# AES128 register map
Vendor: Texas Instruments
Peripheral module from a debugger description file (folder UCD3138R064RSM).
Registers are 32-bit, write-only, no defined reset value unless marked. A register's access mark holds for its fields unless they carry their own. Offsets are as the file gives them; lines under a group give offsets from that group; [hi:lo] are bit positions; {n}, {i} and the like mark numbered series; 'fields as' and 'values as' point back to an identical list; <NAME> marks a mode.

## AES128 — The AES-128 crypto peripheral accellerates AES-128 block cipher encryption and decryption. The peripheral does also offer hardware features to accellerate cipher modes implemented in software: * CBC-MAC * CBC * CTR * CFB * OFB * PCBC The module provides two data registers that can be input to AES operation. These are termed TXT and BUF. TXT is the AES-128 work buffer, and content changes during an AES operation. Software cannot update TXT during an ongoing AES operation. BUF is an auxiliary 128-bit buffer with multiple purposes: * initialization vector(IV) storage * counter in CTR cipher mode * hold next value of TXT Software can update BUF during an AES operation. This allows software to write next TXT during an ongoing AES operation and hence save AES idle times. INTERNAL_NOTE: The crypto module registers KEY, roundkey, BUF, and TXT and are repurposed as PBIST instruction memory when dft_pbist_testctrl input is active. Switching between the functional and PBIST modes of operation assumes all registers become corrupted, and application must initialize registers before use.
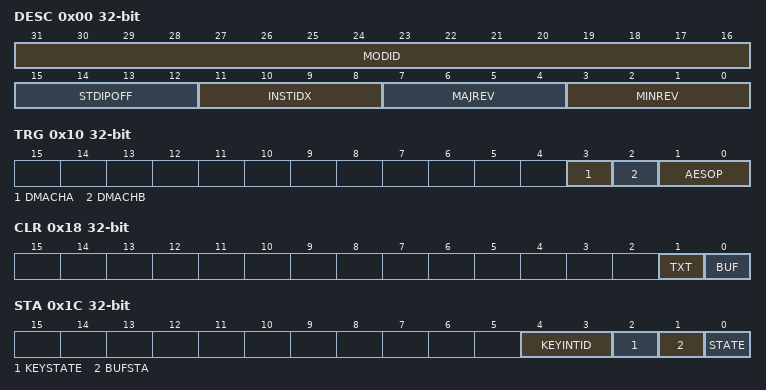
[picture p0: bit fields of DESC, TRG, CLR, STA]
0x00 DESC ro — Description Register. This register provides IP module ID, revision information, instance index and standard MMR registers offset.
  [31:16] MODID — Module Identifier This register is used to uniquely identify this IP.
  [15:12] STDIPOFF — Standard IP MMR block offset Standard IP MMRs are the set from aggregated IRQ registers till DTB. 0: Standard IP MMRs do not exist. 0x1-0xF: Standard IP MMRs begin at offset of 64*[STDIPOFF] from the base IP address.
  [11:8] INSTIDX — IP Instance ID number If multiple instances of IP exist in the device, this field can identify the instance number (0-15).
  [7:4] MAJREV — Major revision of IP (0-15)
  [3:0] MINREV — Minor Revision of IP(0-15)
0x10 TRG — Trigger This register is used to manually trigger operations.
  [3] DMACHA — Manually trigger channel A request
    0=NOEFF (Writing 0 has no effect); 1=SET (Triggers channel A request)
  [2] DMACHB — Manually trigger channel B request
    0=NOEFF (Writing 0 has no effect); 1=SET (Triggers channel B request)
  [1:0] AESOP — AES Operation Write an enumerated value to this field when [STA.STATE] = IDLE to manually trigger an AES operation. If condition is not met, the trigger is ignored. Non-enumerated values are ignored. Enumerated value indicates source of AES operation
    1=TXT (TXT = AES(KEY,TXT)); 2=BUF (TXT = AES(KEY,BUF)); 3=TXTXBUF (TXT = AES(KEY, TXT XOR BUF))
0x14 ABORT — Abort This register is used to abort current AES operation.
  [0] ABORTAES — Abort AES operation Abort an ongoing AES operation. An abort will clear TXT, BUF, DMA, AUTOCFG registers
    0=NOEFF (Writing 0 has no effect); 1=SET (Aborts an ongoing AES operation)
0x18 CLR — Clear This register is used to clear contents of TXT and BUF when [STA.STATE] = IDLE. If condition is not met, the contents remain unchanged.
  [1] TXT — Clear TXT
    0=NOEFF (Writing 0 has no effect); 1=CLR (Clears TXT)
  [0] BUF — Clear BUF
    0=NOEFF (Writing 0 has no effect); 1=CLR (Clears BUF)
0x1C STA ro — Status This register provides information on AES accellerator state and BUF status.
  [4:3] KEYINTID — KEY Initiator ID ID of the most recent AHB Initiator which has written into one of the [KEY0] to [KEY3] registers
    0=CORE (KEY was last written by CM33); 3=HSM (KEY was last written by HSM)
  [2] KEYSTATE — KEY State Indicates whether data in [KEY0] to [KEY3] is valid or not. AES operations are not allowed until KEY is valid
    0=INVALID ([KEY0] to [KEY3] are partially written or empty. Hence they do not have valid KEY value. AES operations are not allowed); 1=VALID ([KEY0] to [KEY3] are completely written by same AHB Initiator . Hence they have valid KEY value. AES operations are allowed.)
  [1] BUFSTA — BUF Status Field gives the status of BUF, indicating EMPTY or FULL, when [AUTOCFG.TRGAES] = WRBUF3. If [AUTOCFG.TRGAES] != WRBUF3, then [STA.BUFSTA] will hold the value 0. Note : Useful for CBC-MAC
    0=EMPTY (Data stored in BUF is already consumed by the AES engine and next block of data can be written in BUF.); 1=FULL (Data stored in BUF is not yet consumed by the AES engine. Next block of data cannot be written into BUF until [STA.STATE] = IDLE.)
  [0] STATE — State Field gives the state of the AES engine.
    0=IDLE (AES engine is IDLE); 1=BUSY (AES operation active)
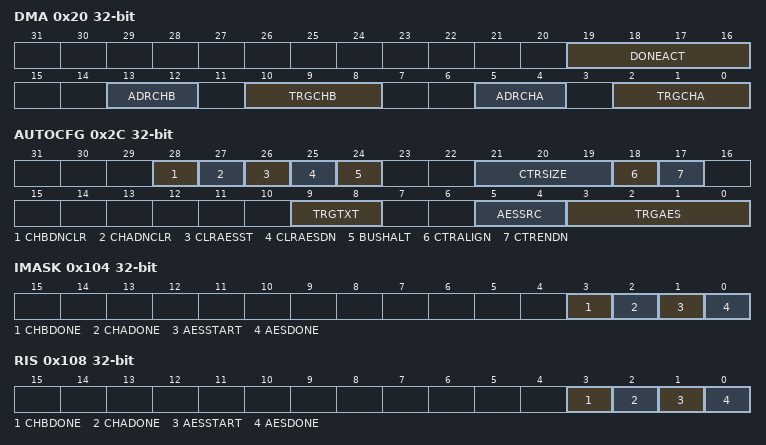
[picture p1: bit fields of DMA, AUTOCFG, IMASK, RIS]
0x20 DMA rw — Direct Memory Access This register controls the conditions that will generate burst requests on each DMA channel.
  [19:16] DONEACT — Done Action This field determines the side effects of DMA done. It is allowed to configure this field with an OR-combination of supported enums, with the exception that GATE_TRGAES_ON_CHA and GATE_TRGAES_ON_CHA_DEL must be mutually exclusive
    0=DIS (DMA done has no side effect); 1=GATE_TRGAES_ON_CHA (Triggers defined in [AUTOCFG.TRGAES] are gated when [RIS.CHADONE] = SET); 2=GATE_TRGAES_ON_CHA_DEL (Delayed gating of triggers defined in [AUTOCFG.TRGAES] Due to the pipelining of BUF writes, in certain modes, DMA CHA Done appears before the last but one AES operation has completed. Setting this bit, will gate the triggers defined in [AUTOCFG.TRGAES] only after the last write by CHA is consumed by AES FSM. Used in ECB,CBC,CBC-MAC modes (having multiple blocks encryption/decryption) to avoid spurious AES operation triggered on last read by CHB. For single mode operation, [DMA.GATE_TRGAES_ON_CHA] must be used.); 4=CLR_TXT_ON_CHA (DMA channel A done event clears [TXT0.*] thru [TXT3.*] if [STA.STATE] = IDLE. Event is ignored if condition is not met.); 8=CLR_TXT_ON_CHB (DMA channel B done event clears [TXT0.*] thru [TXT3.*] if [STA.STATE] = IDLE. Event is ignored if condition is not met.)
  [13:12] ADRCHB — Channel B Read Write Address The DMA accesses [DMACHB.*] to read or write contents of TXT and BUF as a response to a burst request. This field specifes the start address of the first DMA transfer that follows the burst request. The internal address gets incremented automatically for subsequent accesses. The DMA can transfer 8-bit, 16-bit, or 32-bit words, and must always complete a 16-byte transfer before re-arbitration. INTERNAL_NOTE: Upon each channel B request, the internal address counter gets re-initialized to 0.
    0=TXT0 (Start address is [TXT0.*]); 1=TXTX0 (Start address is [TXTX0.*]); 2=BUF0 (Start address is [BUF0.*]); 3=TXTXBUF0 (Start address is [TXTXBUF0.*])
  [10:8] TRGCHB — Channel B Trigger Select the condition that triggers DMA channel B request. Non-enumerated values are not supported and ignored.
    0=DIS (DMA requests are disabled); 1=AESSTART (Start of AES operation triggers request); 2=AESDONE (Completion of AES operation triggers request); 3=WRTXT3 (Writes to [TXT3.*], [TXTX3.*], or [TXTXBUF3.*] trigger request INTERNAL_NOTE: Useful for CFB encryption.); 4=RDTXT3 (Reads of [TXT3.*], or [TXTXBUF3.*] trigger request INTERNAL_NOTE: Useful for PCBC encryption.)
  [5:4] ADRCHA — Channel A Read Write Address The DMA accesses [DMACHA.*] to read or write contents of TXT and BUF as a response to a burst request. This field specifes the start address of the first DMA transfer that follows the burst request. The internal address gets incremented automatically for subsequent accesses. The DMA can transfer 8-bit, 16-bit, or 32-bit words, and must always complete a 16-byte transfer before re-arbitration. INTERNAL_NOTE: Upon each channel A request, the internal address counter gets re-initialized to 0.
    values as ADRCHB
  [2:0] TRGCHA — Channel A Trigger Select the condition that triggers DMA channel A request. Non-enumerated values are not supported and ignored.
    0=DIS (DMA requests are disabled); 1=AESSTART (Start of AES operation triggers request); 2=AESDONE (Completion of AES operation triggers request); 3=WRTXT3 (Writes to [TXT3.*] or [TXTX3.*] trigger request INTERNAL_NOTE: Useful for CFB encryption.); 4=RDTXT3 (Reads of [TXT3.*] or [TXTXBUF3.*] trigger request INTERNAL_NOTE: Useful for PCBC encryption.)
0x24 DMACHA rw — DMA Channel A data transfer DMA accesses this register to read or write contents from sequential addresses specifed by [DMA.ADRCHA].
  [31:0] VAL — Value transferred through DMA Channel A
0x28 DMACHB rw — DMA Channel B data transfer DMA accesses this register to read or write contents from sequential addresses specifed by [DMA.ADRCHB].
  [31:0] VAL — Value transferred through DMA Channel B
0x2C AUTOCFG rw — Automatic Configuration This register configures automatic hardware updates to TXT and BUF. Configure this register to reduce software overhead during cipher modes.
  [28] CHBDNCLR — This field enable auto-clear of [RIS.CHBDONE] interrupt on read/write of [TXT3.*]/[BUF3.*]/[TXTX3.*]/[TXTXBUF3.*] . INTERNAL_NOTE: If conditions for setting and clearing of interrupts occur at the same time, interrupt set will take priority over clear.
    0=DIS (Disable auto-clear of [RIS.CHBDONE] interrupt); 1=EN (Enable auto-clear of [RIS.CHBDONE] interrupt)
  [27] CHADNCLR — This field enables auto-clear of [RIS.CHADONE] interrupt on read/write of [TXT3.*]/[BUF3.*]/[TXTX3.*]/[TXTXBUF3.*] . INTERNAL_NOTE: If conditions for setting and clearing of interrupts occur at the same time, interrupt set will take priority over clear.
    0=DIS (Disable auto-clear of [RIS.CHADONE] interrupt); 1=EN (Enable auto-clear of [RIS.CHADONE] interrupt)
  [26] CLRAESST — Clear AES Start This field enables auto-clear of [RIS.AESSTART] interrupt on read/write of [TXT3.*]/[BUF3.*]/[TXTX3.*]/[TXTXBUF3.*] . INTERNAL_NOTE: If conditions for setting and clearing of interrupts occur at the same time, interrupt set will take priority over clear.
    0=DIS (Disable auto-clear of [RIS.AESSTART] interrupt); 1=EN (Enable auto-clear of [RIS.AESSTART] interrupt)
  [25] CLRAESDN — Clear AES Done This field enables auto-clear of [RIS.AESDONE] interrupt on read/write of [TXT3.*]/[BUF3.*]/[TXTX3.*]/[TXTXBUF3.*] . INTERNAL_NOTE: If conditions for setting and clearing of interrupts occur at the same time, interrupt set will take priority over clear.
    0=DIS (Disable auto-clear of [RIS.AESDONE] interrupt); 1=EN (Enable auto-clear of [RIS.AESDONE] interrupt)
  [24] BUSHALT — Bus Halt This field decides if bus halts on access to KEY, TXT, BUF, TXTX and TXTXBUF when [STA.STATE] = BUSY.
    0=DIS (Disable bus halt When [STA.STATE] = BUSY, writes to KEY, TXT, TXTX are ignored, reads from TXT, TXTXBUF return zero. When [STA.STATE] = BUSY and if either [STA.BUFSTA] = FULL or [AUTOCFG.CTRSIZE] != DISABLE, writes to BUF are ignored, reads return zero.); 1=EN (Enable bus halt When [STA.STATE] = BUSY, access to KEY, TXT, TXTX, TXTXBUF halt the bus until [STA.STATE] = IDLE. When [STA.STATE] = BUSY and if either [STA.BUFSTA] = FULL or [AUTOCFG.CTRSIZE] != DISABLE, access to BUF halts the bus until [STA.STATE] = IDLE.)
  [21:19] CTRSIZE — Counter Size Configures size of counter as either 8,16,32,64 or 128 Non-enumerated values are not supported and ignored
    0=DIS (Disable CTR operation); 1=CTR8 (Configures counter size as 8-bit); 2=CTR16 (Configures counter size as 16-bit); 3=CTR32 (Configures counter size as 32-bit); 4=CTR64 (Configures counter size as 64-bit); 5=CTR128 (Configures counter size as 128-bit)
  [18] CTRALIGN — Counter Alignment Specifies alignment of counter
    0=LEFTALIGN (Indicates Left Aligned Counter Not applicable for 128-bit counter size. For 128-bit counter, all octets will be considered When left aligned,,octet 0-7 will be considered , based on counter size and endianness); 1=RIGHTALIGN (Indicates right aligned counter Not applicable when counter size is 128-bit For 128-bit counter, all octets will be considered If right aligned, octet 8-15 will be considered based on endianness and counter size)
  [17] CTRENDN — Counter Endianness Specifies Endianness of counter
    0=LITTLEENDIAN (Specifies Little Endian Counter Carry will flow from octet 'n' to octet 'n+1'); 1=BIGENDIAN (Specifies Big Endian Counter Carry will flow from octet 'n' to octet 'n-1')
  [9:8] TRGTXT — Trigger for TXT This field determines if and when hardware automatically XORs BUF into TXT. Non-enumerated values are not supported and ignored. It is allowed to configure this field with an OR-combination of supported enums.
    0=DIS (No hardware update of TXT); 1=RDTXT3 (Hardware XORs content of BUF into TXT upon read of [TXT3.*]); 2=RDTXTXBUF3 (Hardware XORs content of BUF into TXT upon read of [TXTXBUF3.*])
  [5:4] AESSRC — AES Source This field specifies the data source to hardware-triggered AES operations. Non-enumerated values are not supported and ignored. INTERNAL_NOTE: Forward AES-128 with field set to BUF or TXTXBUF will need an additional clock cycle to complete. There is room for one more data input if later identified.
    values as TRG.AESOP
  [3:0] TRGAES — Trigger Electronic Codebook This field specifies one or more actions that indirectly trigger AES operation. It is allowed to configure this field with an OR-combination of supported enums.
    0=DIS (No user action indirectly triggers AES operation); 1=WRTXT3 (All writes to [TXT3.*] or [TXTX3.*] trigger action, only when [STA.STATE] = IDLE); 2=RDTXT3 (All reads of [TXT3.*] or [TXTXBUF3.*] trigger action, only when [STA.STATE] = IDLE); 4=WRBUF3 (All writes to [BUF3.*] will schedule to trigger action once [STA.STATE] is or becomes IDLE, only when [AUTOCFG.CTRSIZE] = DIS INTERNAL_NOTE: Useful in CBC-MAC); 8=WRBUF3S (Write to [BUF3.*] will schedule to trigger single action once [STA.STATE] is or becomes IDLE. Subsequent writes do not trigger action unless this setting is written again to this field. INTERNAL_NOTE: Useful in CBC, CTR, and CFB encryption.)
{0x50+4i} KEY{i} (i=0..3) — Key Word {i} Write [KEY0.*] through [KEY3.*] to populate the 128-bit key. The key is not consumed by the hardware. It is hence not required to reload the key for subsequent block encryptions/decryptions unless required by the application.
  [31:0] VAL — Value of KEY[{32i+31}:{32i}]
{0x70+4i} TXT{i} rw (i=0..2) — Text Word {i} TXT is the 128-bit buffer, the AES-128 algorithm performs its operations on. AES input can be written to TXT, and ciphertext can be read from TXT.
  [31:0] VAL — Value of TXT[{32i+31}:{32i}]
0x7C TXT3 rw — Text Word 3 TXT is the 128-bit buffer, the AES-128 algorithm performs its operations on. AES input can be written to TXT, and ciphertext can be read from TXT.
  [31:0] VAL — Value of TXT[127:96] [AUTOCFG.TRGAES] decides if a write to or a read of this field triggers an AES operation.
{0x80+4i} TXTX{i} (i=0..2) — Text Word {i} XOR Write data to this register to XOR data with contents in [TXT{i}.VAL].
  [31:0] VAL — Value in TXT{i} will be [TXT{i}.VAL] = VAL XOR [TXT{i}.VAL]
0x8C TXTX3 — Text Word 3 XOR Write data to this register to XOR data with contents in [TXT3.VAL]. [AUTOCFG.TRGAES] decides if a write to or a read of this field triggers an AES operation.
  [31:0] VAL — Value in TXT3 will be [TXT3.VAL] = VAL XOR [TXT3.VAL]
{0x90+4i} BUF{i} rw (i=0..2) — Buffer Word {i} BUF is a 128-bit auxiliary register that functions as a buffer, counter, or storage of operations in cipher modes.
  [31:0] VAL — Value of BUF[{32i+31}:{32i}]
0x9C BUF3 rw — Buffer Word 3 BUF is a 128-bit auxiliary register that functions as a buffer, counter, or storage of operations in cipher modes. [AUTOCFG.TRGAES] decides if a write to this field triggers an AES operation.
  [31:0] VAL — Value of BUF[127:96]
{0xA0+4i} TXTXBUF{i} ro (i=0..2) — Text Word {i} XOR Buffer Word {i} Read this register to obtain plaintext during CFB decryption. INTERNAL_NOTE: The xor+mux implementatation already, add to readback mux.
  [31:0] VAL — Value read will be [TXT{i}.VAL] XOR [BUF{i}.VAL]
0xAC TXTXBUF3 ro — Text Word 3 XOR Buffer Word3 Read this register to obtain plaintext during CFB decryption. INTERNAL_NOTE: The xor+mux implementatation already, add to readback mux.
  [31:0] VAL — Value read will be [TXT3.VAL] XOR [BUF3.VAL]
0x104 IMASK rw — Interrupt Mask register
  [all] fields
    0=DIS (Disable interrupt mask); 1=EN (Enable interrupt mask)
  [3] CHBDONE — DMA Channel B Done interrupt mask
  [2] CHADONE — DMA Channel A Done interrupt mask
  [1] AESSTART — AES Start interrupt mask
  [0] AESDONE — AES Done interrupt mask
0x108 RIS ro — Raw Interrupt Status register
  [all] fields
    0=CLR (Interrupt did not occur); 1=SET (Interrupt occurred)
  [3] CHBDONE — Raw Interrupt Status for DMA Channel B Done
  [2] CHADONE — Raw Interrupt Status for DMA Channel A Done
  [1] AESSTART — Raw Interrupt Status for AES Start
  [0] AESDONE — Raw Interrupt Status for AES Done
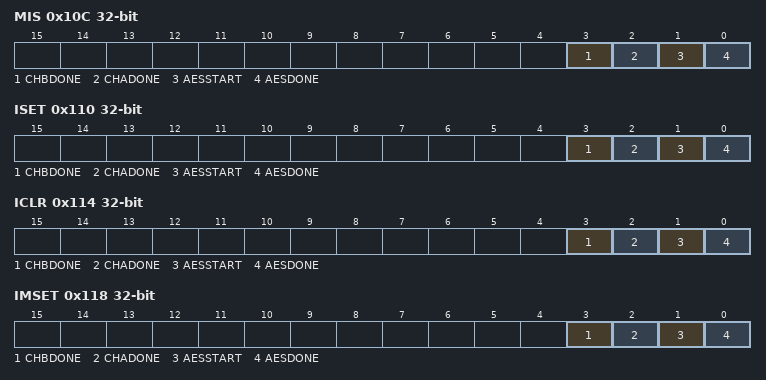
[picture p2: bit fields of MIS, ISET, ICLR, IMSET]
0x10C MIS ro — Masked Interrupt Status register
  [all] fields
    0=CLR (Interrupt did not occur); 1=SET (Interrupt occurred)
  [3] CHBDONE — Masked Interrupt Status for DMA Channel B Done
  [2] CHADONE — Masked Interrupt Status for DMA Channel A Done
  [1] AESSTART — Masked Interrupt Status for AES Start
  [0] AESDONE — Masked Interrupt Status for AES Done
0x110 ISET — Interrupt Set register
  [all] fields
    0=NOEFF (Writing 0 has no effect); 1=SET (Set interrupt)
  [3] CHBDONE — Set DMA Channel B Done interrupt
  [2] CHADONE — Set DMA Channel A Done interrupt
  [1] AESSTART — Set AES Start interrupt
  [0] AESDONE — Set AES Done interrupt
0x114 ICLR — Interrupt Clear register
  [all] fields
    0=NOEFF (Writing 0 has no effect); 1=CLR (Clear interrupt)
  [3] CHBDONE — Clear DMA Channel B Done interrupt
  [2] CHADONE — Clear DMA Channel A Done interrupt
  [1] AESSTART — Clear AES Start interrupt
  [0] AESDONE — Clear AES Done interrupt
0x118 IMSET — Interrupt Mask Set register
  [all] fields
    0=NOEFF (Writing 0 has no effect); 1=SET (Set interrupt mask)
  [3] CHBDONE — Set DMA Channel B Done interrupt mask
  [2] CHADONE — Set DMA Channel A Done interrupt mask
  [1] AESSTART — Set AES Start interrupt mask
  [0] AESDONE — Set AES Done interrupt mask
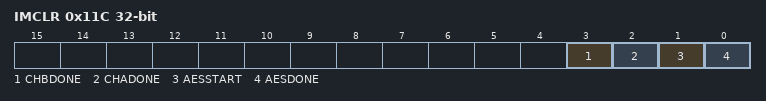
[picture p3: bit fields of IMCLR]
0x11C IMCLR — Interrupt Mask Clear register
  [all] fields
    0=NOEFF (Writing 0 has no effect); 1=CLR (Clear interrupt mask)
  [3] CHBDONE — Clear DMA Channel B Done interrupt mask
  [2] CHADONE — Clear DMA Channel A Done interrupt mask
  [1] AESSTART — Clear AES Start interrupt mask
  [0] AESDONE — Clear AES Done interrupt mask
